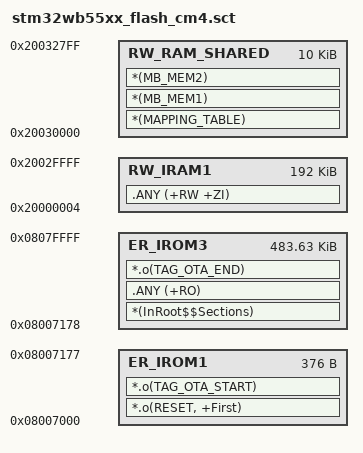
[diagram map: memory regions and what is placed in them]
; *************************************************************
; *** Scatter-Loading Description File generated by uVision ***
; *************************************************************

LR_IROM1 0x08007000 0x178 {    ; load region size_region
  ER_IROM1 0x08007000 0x178  {  ; load address = execution address
    *.o(RESET, +First)
    *.o(TAG_OTA_START) 
  }
  RW_IRAM1     0x20000004 0x2FFFC  {  ; RW data
   .ANY (+RW +ZI)
  }
  RW_RAM_SHARED 0x20030000 0x2800  {  ; RW data
   *(MAPPING_TABLE)
   *(MB_MEM1)
   *(MB_MEM2)
  }
  }
LR_IROM3 0x08007178 0x78E88 {
  ER_IROM3 0x08007178 0x78E88 {  ; load address = execution address   
     *(InRoot$$Sections)
     .ANY (+RO)  
     *.o(TAG_OTA_END)       
  }
  }
